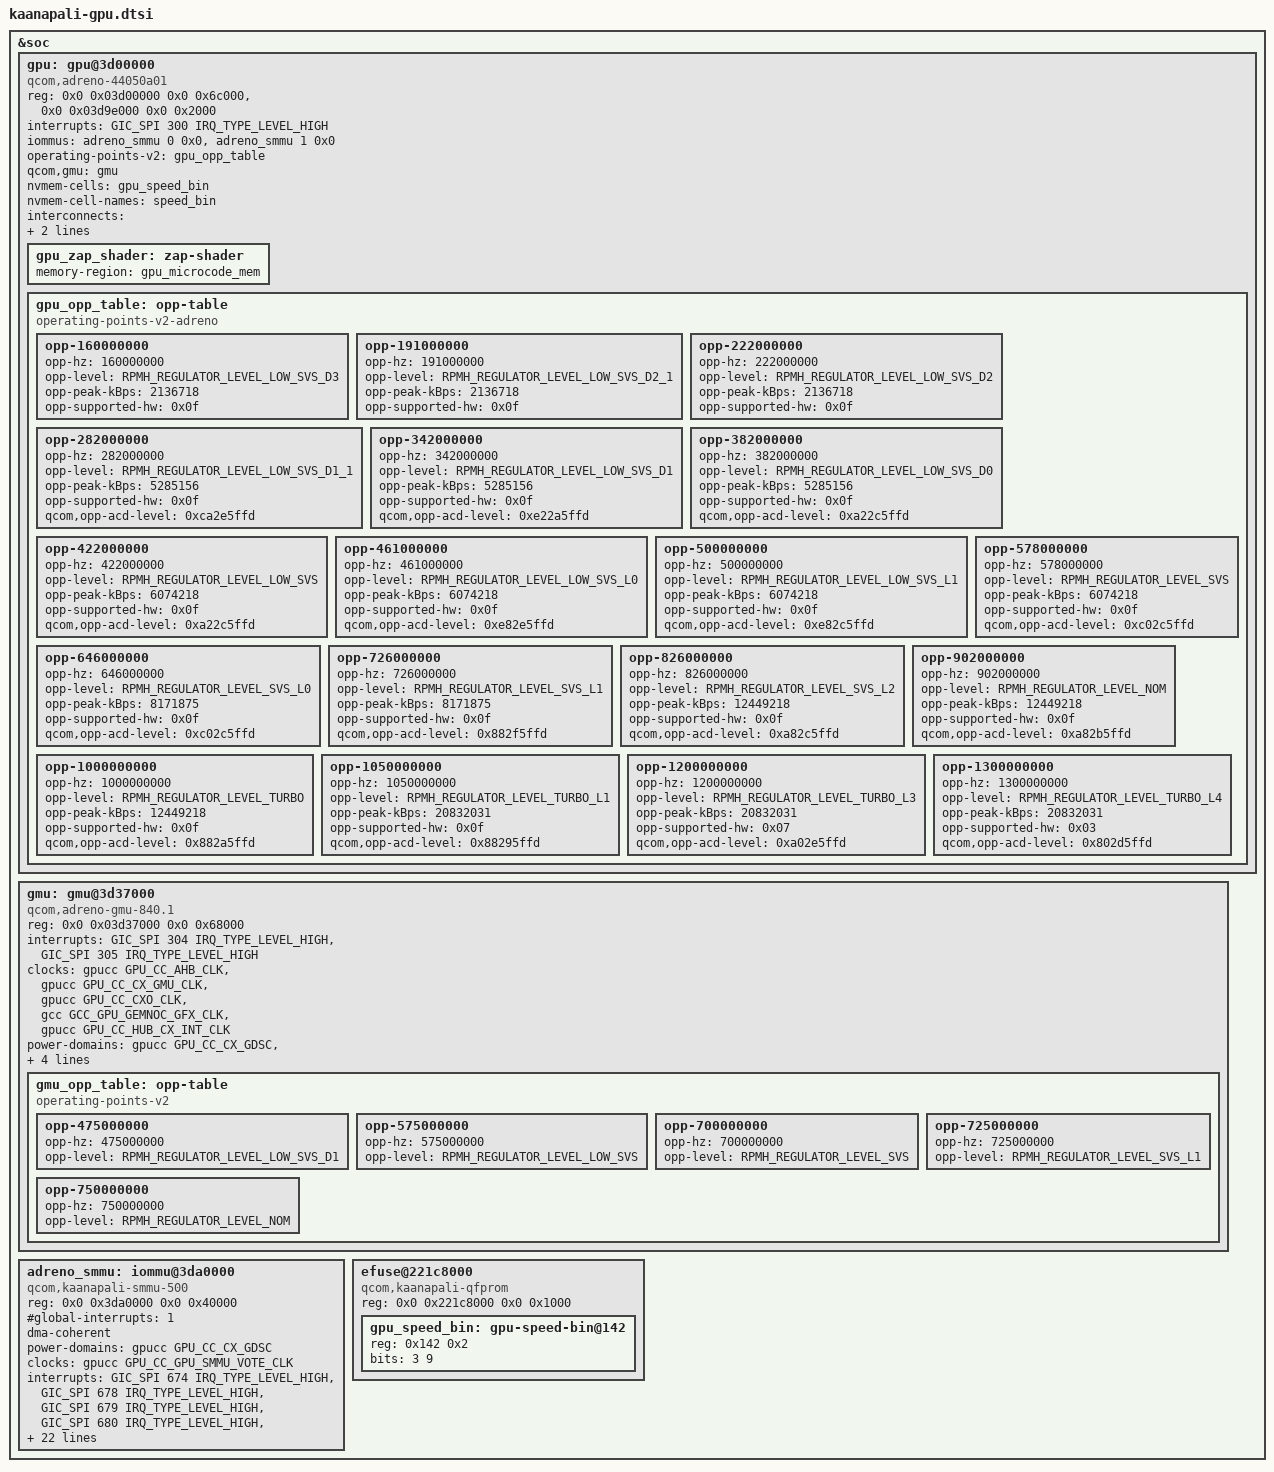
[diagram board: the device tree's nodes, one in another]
// SPDX-License-Identifier: BSD-3-Clause

&soc {
		gpu: gpu@3d00000 {
			compatible = "qcom,adreno-44050a01", "qcom,adreno";
			reg = <0x0 0x03d00000 0x0 0x6c000>,
			      <0x0 0x03d9e000 0x0 0x2000>;
			reg-names = "kgsl_3d0_reg_memory",
				    "cx_mem";

			interrupts = <GIC_SPI 300 IRQ_TYPE_LEVEL_HIGH>;

			iommus = <&adreno_smmu 0 0x0>,
				 <&adreno_smmu 1 0x0>;

			operating-points-v2 = <&gpu_opp_table>;

			qcom,gmu = <&gmu>;
			#cooling-cells = <2>;

			nvmem-cells = <&gpu_speed_bin>;
			nvmem-cell-names = "speed_bin";

			interconnects = <&gem_noc MASTER_GFX3D QCOM_ICC_TAG_ALWAYS
					 &mc_virt SLAVE_EBI1 QCOM_ICC_TAG_ALWAYS>;
			interconnect-names = "gfx-mem";

			gpu_zap_shader: zap-shader {
				memory-region = <&gpu_microcode_mem>;
			};

			gpu_opp_table: opp-table {
				compatible = "operating-points-v2-adreno",
					     "operating-points-v2";

				opp-160000000 {
					opp-hz = /bits/ 64 <160000000>;
					opp-level = <RPMH_REGULATOR_LEVEL_LOW_SVS_D3>;
					opp-peak-kBps = <2136718>;
					opp-supported-hw = <0x0f>;
					/* ACD is disabled */
				};

				opp-191000000 {
					opp-hz = /bits/ 64 <191000000>;
					opp-level = <RPMH_REGULATOR_LEVEL_LOW_SVS_D2_1>;
					opp-peak-kBps = <2136718>;
					opp-supported-hw = <0x0f>;
					/* ACD is disabled */
				};

				opp-222000000 {
					opp-hz = /bits/ 64 <222000000>;
					opp-level = <RPMH_REGULATOR_LEVEL_LOW_SVS_D2>;
					opp-peak-kBps = <2136718>;
					opp-supported-hw = <0x0f>;
					/* ACD is disabled */
				};

				opp-282000000 {
					opp-hz = /bits/ 64 <282000000>;
					opp-level = <RPMH_REGULATOR_LEVEL_LOW_SVS_D1_1>;
					opp-peak-kBps = <5285156>;
					opp-supported-hw = <0x0f>;
					qcom,opp-acd-level = <0xca2e5ffd>;
				};

				opp-342000000 {
					opp-hz = /bits/ 64 <342000000>;
					opp-level = <RPMH_REGULATOR_LEVEL_LOW_SVS_D1>;
					opp-peak-kBps = <5285156>;
					opp-supported-hw = <0x0f>;
					qcom,opp-acd-level = <0xe22a5ffd>;
				};

				opp-382000000 {
					opp-hz = /bits/ 64 <382000000>;
					opp-level = <RPMH_REGULATOR_LEVEL_LOW_SVS_D0>;
					opp-peak-kBps = <5285156>;
					opp-supported-hw = <0x0f>;
					qcom,opp-acd-level = <0xa22c5ffd>;
				};

				opp-422000000 {
					opp-hz = /bits/ 64 <422000000>;
					opp-level = <RPMH_REGULATOR_LEVEL_LOW_SVS>;
					opp-peak-kBps = <6074218>;
					opp-supported-hw = <0x0f>;
					qcom,opp-acd-level = <0xa22c5ffd>;
				};

				opp-461000000 {
					opp-hz = /bits/ 64 <461000000>;
					opp-level = <RPMH_REGULATOR_LEVEL_LOW_SVS_L0>;
					opp-peak-kBps = <6074218>;
					opp-supported-hw = <0x0f>;
					qcom,opp-acd-level = <0xe82e5ffd>;
				};

				opp-500000000 {
					opp-hz = /bits/ 64 <500000000>;
					opp-level = <RPMH_REGULATOR_LEVEL_LOW_SVS_L1>;
					opp-peak-kBps = <6074218>;
					opp-supported-hw = <0x0f>;
					qcom,opp-acd-level = <0xe82c5ffd>;
				};

				opp-578000000 {
					opp-hz = /bits/ 64 <578000000>;
					opp-level = <RPMH_REGULATOR_LEVEL_SVS>;
					opp-peak-kBps = <6074218>;
					opp-supported-hw = <0x0f>;
					qcom,opp-acd-level = <0xc02c5ffd>;
				};

				opp-646000000 {
					opp-hz = /bits/ 64 <646000000>;
					opp-level = <RPMH_REGULATOR_LEVEL_SVS_L0>;
					opp-peak-kBps = <8171875>;
					opp-supported-hw = <0x0f>;
					qcom,opp-acd-level = <0xc02c5ffd>;
				};

				opp-726000000 {
					opp-hz = /bits/ 64 <726000000>;
					opp-level = <RPMH_REGULATOR_LEVEL_SVS_L1>;
					opp-peak-kBps = <8171875>;
					opp-supported-hw = <0x0f>;
					qcom,opp-acd-level = <0x882f5ffd>;
				};

				opp-826000000 {
					opp-hz = /bits/ 64 <826000000>;
					opp-level = <RPMH_REGULATOR_LEVEL_SVS_L2>;
					opp-peak-kBps = <12449218>;
					opp-supported-hw = <0x0f>;
					qcom,opp-acd-level = <0xa82c5ffd>;
				};

				opp-902000000 {
					opp-hz = /bits/ 64 <902000000>;
					opp-level = <RPMH_REGULATOR_LEVEL_NOM>;
					opp-peak-kBps = <12449218>;
					opp-supported-hw = <0x0f>;
					qcom,opp-acd-level = <0xa82b5ffd>;
				};

				opp-1000000000 {
					opp-hz = /bits/ 64 <1000000000>;
					opp-level = <RPMH_REGULATOR_LEVEL_TURBO>;
					opp-peak-kBps = <12449218>;
					opp-supported-hw = <0x0f>;
					qcom,opp-acd-level = <0x882a5ffd>;
				};

				opp-1050000000 {
					opp-hz = /bits/ 64 <1050000000>;
					opp-level = <RPMH_REGULATOR_LEVEL_TURBO_L1>;
					opp-peak-kBps = <20832031>;
					opp-supported-hw = <0x0f>;
					qcom,opp-acd-level = <0x88295ffd>;
				};

				opp-1200000000 {
					opp-hz = /bits/ 64 <1200000000>;
					opp-level = <RPMH_REGULATOR_LEVEL_TURBO_L3>;
					opp-peak-kBps = <20832031>;
					opp-supported-hw = <0x07>;
					qcom,opp-acd-level = <0xa02e5ffd>;
				};

				opp-1300000000 {
					opp-hz = /bits/ 64 <1300000000>;
					opp-level = <RPMH_REGULATOR_LEVEL_TURBO_L4>;
					opp-peak-kBps = <20832031>;
					opp-supported-hw = <0x03>;
					qcom,opp-acd-level = <0x802d5ffd>;
				};
			};
		};

		gmu: gmu@3d37000 {
			compatible = "qcom,adreno-gmu-840.1", "qcom,adreno-gmu";

			reg = <0x0 0x03d37000 0x0 0x68000>;
			reg-names = "gmu";

			interrupts = <GIC_SPI 304 IRQ_TYPE_LEVEL_HIGH>,
				     <GIC_SPI 305 IRQ_TYPE_LEVEL_HIGH>;
			interrupt-names = "hfi", "gmu";

			clocks = <&gpucc GPU_CC_AHB_CLK>,
				 <&gpucc GPU_CC_CX_GMU_CLK>,
				 <&gpucc GPU_CC_CXO_CLK>,
				 <&gcc GCC_GPU_GEMNOC_GFX_CLK>,
				 <&gpucc GPU_CC_HUB_CX_INT_CLK>;
			clock-names = "ahb",
				      "gmu",
				      "cxo",
				      "memnoc",
				      "hub";

			power-domains = <&gpucc GPU_CC_CX_GDSC>,
					<&gxclkctl GX_CLKCTL_GX_GDSC>;
			power-domain-names = "cx",
					     "gx";

			iommus = <&adreno_smmu 5 0x0>;

			qcom,qmp = <&aoss_qmp>;

			operating-points-v2 = <&gmu_opp_table>;

			gmu_opp_table: opp-table {
				compatible = "operating-points-v2";

				opp-475000000 {
					opp-hz = /bits/ 64 <475000000>;
					opp-level = <RPMH_REGULATOR_LEVEL_LOW_SVS_D1>;
				};

				opp-575000000 {
					opp-hz = /bits/ 64 <575000000>;
					opp-level = <RPMH_REGULATOR_LEVEL_LOW_SVS>;
				};

				opp-700000000 {
					opp-hz = /bits/ 64 <700000000>;
					opp-level = <RPMH_REGULATOR_LEVEL_SVS>;
				};

				opp-725000000 {
					opp-hz = /bits/ 64 <725000000>;
					opp-level = <RPMH_REGULATOR_LEVEL_SVS_L1>;
				};

				opp-750000000 {
					opp-hz = /bits/ 64 <750000000>;
					opp-level = <RPMH_REGULATOR_LEVEL_NOM>;
				};
			};
		};

		adreno_smmu: iommu@3da0000 {
			compatible = "qcom,kaanapali-smmu-500", "qcom,adreno-smmu",
					"qcom,smmu-500", "arm,mmu-500";
			reg = <0x0 0x3da0000 0x0 0x40000>;
			#iommu-cells = <2>;
			#global-interrupts = <1>;
			dma-coherent;

			power-domains = <&gpucc GPU_CC_CX_GDSC>;

			clocks = <&gpucc GPU_CC_GPU_SMMU_VOTE_CLK>;
			clock-names = "hlos";

			interrupts = <GIC_SPI 674 IRQ_TYPE_LEVEL_HIGH>,
				<GIC_SPI 678 IRQ_TYPE_LEVEL_HIGH>,
				<GIC_SPI 679 IRQ_TYPE_LEVEL_HIGH>,
				<GIC_SPI 680 IRQ_TYPE_LEVEL_HIGH>,
				<GIC_SPI 681 IRQ_TYPE_LEVEL_HIGH>,
				<GIC_SPI 682 IRQ_TYPE_LEVEL_HIGH>,
				<GIC_SPI 683 IRQ_TYPE_LEVEL_HIGH>,
				<GIC_SPI 684 IRQ_TYPE_LEVEL_HIGH>,
				<GIC_SPI 685 IRQ_TYPE_LEVEL_HIGH>,
				<GIC_SPI 686 IRQ_TYPE_LEVEL_HIGH>,
				<GIC_SPI 687 IRQ_TYPE_LEVEL_HIGH>,
				<GIC_SPI 688 IRQ_TYPE_LEVEL_HIGH>,
				<GIC_SPI 422 IRQ_TYPE_LEVEL_HIGH>,
				<GIC_SPI 476 IRQ_TYPE_LEVEL_HIGH>,
				<GIC_SPI 574 IRQ_TYPE_LEVEL_HIGH>,
				<GIC_SPI 575 IRQ_TYPE_LEVEL_HIGH>,
				<GIC_SPI 576 IRQ_TYPE_LEVEL_HIGH>,
				<GIC_SPI 577 IRQ_TYPE_LEVEL_HIGH>,
				<GIC_SPI 660 IRQ_TYPE_LEVEL_HIGH>,
				<GIC_SPI 662 IRQ_TYPE_LEVEL_HIGH>,
				<GIC_SPI 665 IRQ_TYPE_LEVEL_HIGH>,
				<GIC_SPI 666 IRQ_TYPE_LEVEL_HIGH>,
				<GIC_SPI 667 IRQ_TYPE_LEVEL_HIGH>,
				<GIC_SPI 669 IRQ_TYPE_LEVEL_HIGH>,
				<GIC_SPI 670 IRQ_TYPE_LEVEL_HIGH>,
				<GIC_SPI 700 IRQ_TYPE_LEVEL_HIGH>;
		};

		efuse@221c8000 {
			compatible = "qcom,kaanapali-qfprom", "qcom,qfprom";
			reg = <0x0 0x221c8000 0x0 0x1000>;
			#address-cells = <1>;
			#size-cells = <1>;

			gpu_speed_bin: gpu-speed-bin@142 {
				reg = <0x142 0x2>;
				bits = <3 9>;
			};
		};
};
